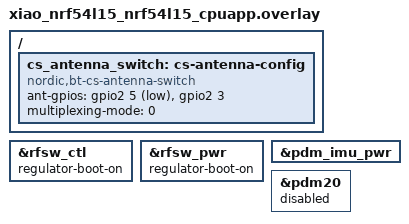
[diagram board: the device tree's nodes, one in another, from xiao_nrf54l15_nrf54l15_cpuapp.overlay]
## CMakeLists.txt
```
cmake_minimum_required(VERSION 3.20.0)
find_package(Zephyr REQUIRED HINTS $ENV{ZEPHYR_BASE})

project(Garage)

target_sources(app PRIVATE src/main.cpp ../src/blinker.cpp src/ble_reflector.cpp ../src/PairingConfig.cpp)
```

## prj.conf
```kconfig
#
# Copyright (c) 2024 Nordic Semiconductor ASA
#
# SPDX-License-Identifier: LicenseRef-Nordic-5-Clause
#

# Minimal config for Xiao nRF54L15 (no external memory)
CONFIG_GPIO=y
CONFIG_REBOOT=y

# Force SoftDevice Controller only (disable Zephyr controller)
CONFIG_BT_LL_SW_SPLIT=n

CONFIG_BT=y
CONFIG_BT_PERIPHERAL=y
CONFIG_BT_SMP=y
CONFIG_BT_DEVICE_NAME="Car_1"
CONFIG_BT_MAX_CONN=1
CONFIG_BT_GAP_AUTO_UPDATE_CONN_PARAMS=n
CONFIG_BT_BONDABLE=y

# The Ranging Profile recommends a MTU of at least 247 octets.
CONFIG_BT_L2CAP_TX_MTU=498
CONFIG_BT_BUF_ACL_TX_SIZE=502
CONFIG_BT_BUF_ACL_RX_SIZE=502
CONFIG_BT_CTLR_DATA_LENGTH_MAX=251
CONFIG_BT_CTLR_PHY_2M=y

# Ensure Event RX count is greater than ACL TX count
CONFIG_BT_BUF_ACL_TX_COUNT=3
CONFIG_BT_BUF_EVT_RX_COUNT=20
CONFIG_BT_L2CAP_TX_BUF_COUNT=10
CONFIG_BT_BUF_EVT_DISCARDABLE_COUNT=15
# CONFIG_HEAP_MEM_POOL_SIZE=4096

# Optional: Increase general heap and buffer sizes for stability
CONFIG_HEAP_MEM_POOL_SIZE=8192

# Single antenna configuration for Xiao nRF54L15
CONFIG_BT_RAS_MAX_ANTENNA_PATHS=1
CONFIG_BT_CTLR_SDC_CS_ROLE_REFLECTOR_ONLY=y

# Disabling the CS Test command reduces flash usage
CONFIG_BT_CTLR_CHANNEL_SOUNDING_TEST=n

# This allows CS and ACL to use different PHYs
CONFIG_BT_TRANSMIT_POWER_CONTROL=y

CONFIG_BT_CHANNEL_SOUNDING=y
CONFIG_BT_RAS=y
CONFIG_BT_RAS_RRSP=y

# Console and logging
CONFIG_SERIAL=y
CONFIG_CONSOLE=y
CONFIG_UART_CONSOLE=y
CONFIG_LOG=y
CONFIG_LOG_MODE_IMMEDIATE=n
CONFIG_LOG_DEFAULT_LEVEL=3


# Enable Bluetooth Settings (Persistent Storage)
CONFIG_BT_SETTINGS=y

# Enable Flash and NVS (Non-Volatile Storage)
CONFIG_FLASH=y
CONFIG_FLASH_PAGE_LAYOUT=y
CONFIG_FLASH_MAP=y
CONFIG_NVS=y
CONFIG_SETTINGS=y
CONFIG_SETTINGS_NVS=y
```

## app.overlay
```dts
&uart20 {
    status = "okay";
    current-speed = <115200>;
};
```

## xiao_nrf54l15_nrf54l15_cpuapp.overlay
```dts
/*
 * Copyright (c) 2025 Nordic Semiconductor ASA
 *
 * SPDX-License-Identifier: LicenseRef-Nordic-5-Clause
 */

/ {
    /* Channel Sounding antenna config using Xiao's RF switch GPIOs */
    cs_antenna_switch: cs-antenna-config {
        status = "okay";
        compatible = "nordic,bt-cs-antenna-switch";
        /* Xiao RF switch control pins */
        ant-gpios = <&gpio2 5 GPIO_ACTIVE_LOW>, /* rfsw-ctl */
                    <&gpio2 3 GPIO_ACTIVE_HIGH>;  /* rfsw-pwr */
        multiplexing-mode = <0>;
    };
};

&rfsw_ctl {
    regulator-boot-on;
};

&rfsw_pwr {
    regulator-boot-on;
};

&pdm_imu_pwr {
    /delete-property/ regulator-boot-on;
};

&pdm20 {
    status = "disabled";
};
```

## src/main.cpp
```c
#include <stdio.h>
#include <zephyr/kernel.h>
#include <zephyr/sys/printk.h>
#include <zephyr/sys/reboot.h>

#include "../../src/blinker.h"
#include "ble_reflector.h"

/* 1000 msec = 1 sec */
#define SLEEP_TIME_MS 2000
#define ON_TIME_MS 150
#define OFF_TIME_MS 100
#define REBOOT_TIME (60 * 30) // * SLEEP_TIME_MS = 1 hour

static uint8_t loopCount = 0;

int main(void)
{
    printk("[main] Starting application\n");

    printk("[main] Initializing Blinker...\n");
    Blinker bl;
    bl.blink(2, ON_TIME_MS, OFF_TIME_MS);
    printk("[main] Blinker initialized\n");

    printk("[main] Initializing Bluetooth...\n");
    BleReflector bleReflector;
    /* Start advertising and enable pairing (uses shared PAIRING_PIN) */
    if (bleReflector.init())
    {
        printk("[main] Bluetooth initialized\n");
    }
    else
    {
        printk("[main] Bluetooth initialization failed\n");
    }

    printk("[main] Requesting blink patterns\n");
    while (1)
    {
        if (bleReflector.connected())
        {
            bl.blink(1, ON_TIME_MS * 2, OFF_TIME_MS);
        }
        else
        {
            bl.blink(2, ON_TIME_MS, OFF_TIME_MS);
        }

        if (loopCount++ > REBOOT_TIME)
        {
            printk("[main] Rebooting (cold) after %d loops\n", loopCount);
            sys_reboot(SYS_REBOOT_COLD);
        }
        k_msleep(SLEEP_TIME_MS);
    }
    return 0;
}
```

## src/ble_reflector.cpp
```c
#include <zephyr/types.h>
#include <zephyr/kernel.h>
#include <zephyr/bluetooth/bluetooth.h>
#include <zephyr/sys/byteorder.h>
#include <zephyr/sys/reboot.h>
#include <zephyr/bluetooth/conn.h>
#include <zephyr/bluetooth/uuid.h>
#include <zephyr/bluetooth/cs.h>
#include <bluetooth/services/ras.h>
#include <zephyr/settings/settings.h>

#include <zephyr/drivers/gpio.h>

#include <zephyr/logging/log.h>
LOG_MODULE_REGISTER(app_main, LOG_LEVEL_INF);

#include "ble_reflector.h"
#include "../../src/PairingConfig.h"

static K_SEM_DEFINE(sem_connected, 0, 1);
static K_SEM_DEFINE(sem_config, 0, 1);

static struct bt_conn *connection;

/* Thread to configure default Channel Sounding settings after connection */
K_THREAD_STACK_DEFINE(cs_stack, 1024);

static void connected_cb(struct bt_conn *conn, uint8_t err)
{
    char addr[BT_ADDR_LE_STR_LEN];

    (void)bt_addr_le_to_str(bt_conn_get_dst(conn), addr, sizeof(addr));
    LOG_INF("Connected to %s (err 0x%02X)", addr, err);

    if (err)
    {
        bt_conn_unref(conn);
        connection = NULL;
    }
    else
    {
        connection = bt_conn_ref(conn);

        k_sem_give(&sem_connected);
    }
}

static void disconnected_cb(struct bt_conn *conn, uint8_t reason)
{
    LOG_INF("Disconnected (reason 0x%02X)", reason);

    bt_conn_unref(conn);
    connection = NULL;

    sys_reboot(SYS_REBOOT_COLD);
}

static void remote_capabilities_cb(struct bt_conn *conn,
                                   uint8_t status,
                                   struct bt_conn_le_cs_capabilities *params)
{
    ARG_UNUSED(conn);
    ARG_UNUSED(params);

    if (status == BT_HCI_ERR_SUCCESS)
    {
        LOG_INF("CS capability exchange completed.");
    }
    else
    {
        LOG_WRN("CS capability exchange failed. (HCI status 0x%02x)", status);
    }
}

static void config_create_cb(struct bt_conn *conn, uint8_t status, struct bt_conn_le_cs_config *config)
{
    ARG_UNUSED(conn);

    if (status == BT_HCI_ERR_SUCCESS)
    {
        const char *mode_str[5] = {"Unused", "1 (RTT)", "2 (PBR)", "3 (RTT + PBR)", "Invalid"};
        const char *role_str[3] = {"Initiator", "Reflector", "Invalid"};
        const char *rtt_type_str[8] = {
            "AA only", "32-bit sounding", "96-bit sounding", "32-bit random",
            "64-bit random", "96-bit random", "128-bit random", "Invalid"};
        const char *phy_str[4] = {"Invalid", "LE 1M PHY", "LE 2M PHY", "LE 2M 2BT PHY"};
        const char *chsel_type_str[3] = {"Algorithm #3b", "Algorithm #3c", "Invalid"};
        const char *ch3c_shape_str[3] = {"Hat shape", "X shape", "Invalid"};

        uint8_t mode_idx = config->mode > 0 && config->mode < 4 ? config->mode : 4;
        uint8_t role_idx = MIN(config->role, 2);
        uint8_t rtt_type_idx = MIN(config->rtt_type, 7);
        uint8_t phy_idx = config->cs_sync_phy > 0 && config->cs_sync_phy < 4
                              ? config->cs_sync_phy
                              : 0;
        uint8_t chsel_type_idx = MIN(config->channel_selection_type, 2);
        uint8_t ch3c_shape_idx = MIN(config->ch3c_shape, 2);

        LOG_INF("CS config creation complete.\r\n"
                " - id: %u\r\n"
                " - mode: %s\r\n"
                " - min_main_mode_steps: %u\r\n"
                " - max_main_mode_steps: %u\r\n"
                " - main_mode_repetition: %u\r\n"
                " - mode_0_steps: %u\r\n"
                " - role: %s\r\n"
                " - rtt_type: %s\r\n"
                " - cs_sync_phy: %s\r\n"
                " - channel_map_repetition: %u\r\n"
                " - channel_selection_type: %s\r\n"
                " - ch3c_shape: %s\r\n"
                " - ch3c_jump: %u\r\n"
                " - t_ip1_time_us: %u\r\n"
                " - t_ip2_time_us: %u\r\n"
                " - t_fcs_time_us: %u\r\n"
                " - t_pm_time_us: %u\r\n"
                " - channel_map: 0x%08X%08X%04X\r\n",
                config->id, mode_str[mode_idx],
                config->min_main_mode_steps, config->max_main_mode_steps,
                config->main_mode_repetition, config->mode_0_steps, role_str[role_idx],
                rtt_type_str[rtt_type_idx], phy_str[phy_idx],
                config->channel_map_repetition, chsel_type_str[chsel_type_idx],
                ch3c_shape_str[ch3c_shape_idx], config->ch3c_jump, config->t_ip1_time_us,
                config->t_ip2_time_us, config->t_fcs_time_us, config->t_pm_time_us,
                sys_get_le32(&config->channel_map[6]),
                sys_get_le32(&config->channel_map[2]),
                sys_get_le16(&config->channel_map[0]));

        k_sem_give(&sem_config);
    }
    else
    {
        LOG_WRN("CS config creation failed. (HCI status 0x%02x)", status);
    }
}

static void security_enable_cb(struct bt_conn *conn, uint8_t status)
{
    ARG_UNUSED(conn);

    if (status == BT_HCI_ERR_SUCCESS)
    {
        LOG_INF("CS security enabled.");
    }
    else
    {
        LOG_WRN("CS security enable failed. (HCI status 0x%02x)", status);
    }
}

static void procedure_enable_cb(struct bt_conn *conn,
                                uint8_t status,
                                struct bt_conn_le_cs_procedure_enable_complete *params)
{
    ARG_UNUSED(conn);

    if (status == BT_HCI_ERR_SUCCESS)
    {
        if (params->state == 1)
        {
            LOG_INF("CS procedures enabled:\r\n"
                    " - config ID: %u\r\n"
                    " - antenna configuration index: %u\r\n"
                    " - TX power: %d dbm\r\n"
                    " - subevent length: %u us\r\n"
                    " - subevents per event: %u\r\n"
                    " - subevent interval: %u\r\n"
                    " - event interval: %u\r\n"
                    " - procedure interval: %u\r\n"
                    " - procedure count: %u\r\n"
                    " - maximum procedure length: %u",
                    params->config_id, params->tone_antenna_config_selection,
                    params->selected_tx_power, params->subevent_len,
                    params->subevents_per_event, params->subevent_interval,
                    params->event_interval, params->procedure_interval,
                    params->procedure_count, params->max_procedure_len);
        }
        else
        {
            LOG_INF("CS procedures disabled.");
        }
    }
    else
    {
        LOG_WRN("CS procedures enable failed. (HCI status 0x%02x)", status);
    }
}

BT_CONN_CB_DEFINE(conn_cb) = {
    .connected = connected_cb,
    .disconnected = disconnected_cb,
    .le_cs_read_remote_capabilities_complete = remote_capabilities_cb,
    .le_cs_config_complete = config_create_cb,
    .le_cs_security_enable_complete = security_enable_cb,
    .le_cs_procedure_enable_complete = procedure_enable_cb,
};

static struct k_thread cs_thread_data;
static void cs_thread(void *p1, void *p2, void *p3)
{
    int err;
    while (true)
    {
        k_sem_take(&sem_connected, K_FOREVER);

        const struct bt_le_cs_set_default_settings_param default_settings = {
            .enable_initiator_role = false,
            .enable_reflector_role = true,
            .cs_sync_antenna_selection = BT_LE_CS_ANTENNA_SELECTION_OPT_REPETITIVE,
            .max_tx_power = BT_HCI_OP_LE_CS_MAX_MAX_TX_POWER,
        };

        err = bt_le_cs_set_default_settings(connection, &default_settings);
        if (err)
        {
            LOG_ERR("Failed to configure default CS settings (err %d)", err);
        }

        k_sem_take(&sem_config, K_FOREVER);

        const struct bt_le_cs_set_procedure_parameters_param procedure_params = {
            .config_id = 0,
            .max_procedure_len = 1000,
            .min_procedure_interval = 1,
            .max_procedure_interval = 100,
            .max_procedure_count = 0,
            .min_subevent_len = 10000,
            .max_subevent_len = 75000,
            .tone_antenna_config_selection = BT_LE_CS_TONE_ANTENNA_CONFIGURATION_A1_B1,
            .phy = BT_LE_CS_PROCEDURE_PHY_2M,
            .tx_power_delta = (int8_t)0x80,
            .preferred_peer_antenna = BT_LE_CS_PROCEDURE_PREFERRED_PEER_ANTENNA_1,
            .snr_control_initiator = BT_LE_CS_SNR_CONTROL_NOT_USED,
            .snr_control_reflector = BT_LE_CS_SNR_CONTROL_NOT_USED,
        };

        err = bt_le_cs_set_procedure_parameters(connection, &procedure_params);
        if (err)
        {
            LOG_ERR("Failed to set procedure parameters (err %d)", err);
            return;
        }
    }
}

static const struct bt_data ad[] = {
    BT_DATA_BYTES(BT_DATA_FLAGS, (BT_LE_AD_GENERAL | BT_LE_AD_NO_BREDR)),
    BT_DATA_BYTES(BT_DATA_UUID16_ALL, BT_UUID_16_ENCODE(BT_UUID_RANGING_SERVICE_VAL)),
    BT_DATA(BT_DATA_NAME_COMPLETE, CONFIG_BT_DEVICE_NAME, sizeof(CONFIG_BT_DEVICE_NAME) - 1),
    BT_DATA_BYTES(BT_DATA_UUID16_ALL, BT_UUID_16_ENCODE(0xA455)),
};

bool BleReflector::init()
{
    int err;

    LOG_INF("Starting Channel Sounding Reflector Sample");

    /* Configure RF switch - EXPERIMENTAL: Change these values to find correct antenna */
    /* rfsw-pwr (GPIO2.3): HIGH=enable switch, LOW=disable */
    /* rfsw-ctl (GPIO2.5): Controls antenna selection (try HIGH and LOW) */
    const struct device *gpio2 = DEVICE_DT_GET(DT_NODELABEL(gpio2));
    if (device_is_ready(gpio2))
    {
        gpio_pin_configure(gpio2, 3, GPIO_OUTPUT_ACTIVE); /* rfsw-pwr = HIGH */
        gpio_pin_configure(gpio2, 5, GPIO_OUTPUT_ACTIVE); /* rfsw-ctl = LOW (try changing to ACTIVE) */
        LOG_INF("RF switch: pwr=HIGH, ctl=LOW");
    }

    err = bt_enable(NULL);
    if (err)
    {
        LOG_ERR("Bluetooth init failed (err %d)", err);
        return false;
    }

    if (IS_ENABLED(CONFIG_BT_SETTINGS))
    {
        settings_load();
    }

    PairingConfig::init(NULL);

    err = bt_le_adv_start(BT_LE_ADV_CONN_FAST_2, ad, ARRAY_SIZE(ad), NULL, 0);
    if (err)
    {
        LOG_ERR("Advertising failed to start (err %d)", err);
        return false;
    }

    /* Spawn background thread to configure default CS settings when connected */
    k_thread_create(&cs_thread_data,
                    cs_stack,
                    K_THREAD_STACK_SIZEOF(cs_stack),
                    cs_thread,
                    NULL,
                    NULL,
                    NULL,
                    K_PRIO_PREEMPT(7),
                    0,
                    K_NO_WAIT);

    return true;
}

bool BleReflector::connected()
{
    return connection != NULL;
}
```

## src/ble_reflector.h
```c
// Lightweight C++ wrappers for Zephyr BLE Channel Sounding (initiator & reflector)
#ifndef BLE_REFLECTOR_H
#define BLE_REFLECTOR_H

#include <zephyr/bluetooth/conn.h>

class BleReflector
{
public:
    bool init();
    bool connected();

private:
};

#endif // BLE_REFLECTOR_H
```

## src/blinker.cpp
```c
#include "blinker.h"

#include <zephyr/kernel.h>
#include <zephyr/drivers/gpio.h>
#include <zephyr/devicetree.h>
#include <zephyr/sys/printk.h>
#include <atomic>
#include <limits.h>

/* The devicetree node identifier for the "led0" alias. */
#define LED0_NODE DT_ALIAS(led0)

static const struct gpio_dt_spec led = GPIO_DT_SPEC_GET_OR(LED0_NODE, gpios, {0});

/* Thread + stack for blinking */
static K_THREAD_STACK_DEFINE(blinker_stack, 512);
static struct k_thread blinker_thread;
static struct k_sem blinker_sem;

static std::atomic<bool> blinker_cancel{false};
static std::atomic<bool> blinker_ready{false};
static int blinker_number = 0;
static uint32_t blinker_on = 0;
static uint32_t blinker_off = 0;

static void blinker_thread_entry(void *p1, void *p2, void *p3)
{
    ARG_UNUSED(p1);
    ARG_UNUSED(p2);
    ARG_UNUSED(p3);

    while (1)
    {
        k_sem_take(&blinker_sem, K_FOREVER);
        blinker_cancel.store(false);

        int number = blinker_number;
        uint32_t on = blinker_on;
        uint32_t off = blinker_off;

        int loops = (number <= 0) ? INT_MAX : number;

        for (int i = 0; i < loops; ++i)
        {
            if (blinker_cancel.load())
                break;

            gpio_pin_set_dt(&led, 0);
            if (on)
                k_msleep(on);

            if (blinker_cancel.load())
                break;

            gpio_pin_set_dt(&led, 1);
            if (off)
                k_msleep(off);
        }
    }
}

static void ensure_initialized()
{
    bool expected = false;
    if (blinker_ready.compare_exchange_strong(expected, true))
    {
        if (!gpio_is_ready_dt(&led))
        {
            return;
        }

        gpio_pin_configure_dt(&led, GPIO_OUTPUT_INACTIVE);

        k_sem_init(&blinker_sem, 0, 1);

        k_thread_create(&blinker_thread, blinker_stack, K_THREAD_STACK_SIZEOF(blinker_stack),
                        blinker_thread_entry, NULL, NULL, NULL,
                        K_PRIO_PREEMPT(7), 0, K_NO_WAIT);
    }
}

Blinker::Blinker()
{
    ensure_initialized();
}

Blinker::~Blinker()
{
    /* request cancel and wake thread so it stops its current loop */
    blinker_cancel.store(true);
    k_sem_give(&blinker_sem);
}

void Blinker::blink(int number, uint32_t onTimeMs, uint32_t offTimeMs)
{
    ensure_initialized();

    if (!blinker_ready.load())
        return;

    /* request cancel of any running pattern */
    blinker_cancel.store(true);

    /* update parameters for the thread */
    blinker_number = number;
    blinker_on = onTimeMs;
    blinker_off = offTimeMs;

    /* wake the thread to run the new pattern */
    k_sem_give(&blinker_sem);
}
```
